AUTOSAR XML (schema 4-3-0)
package /ComponentTypes
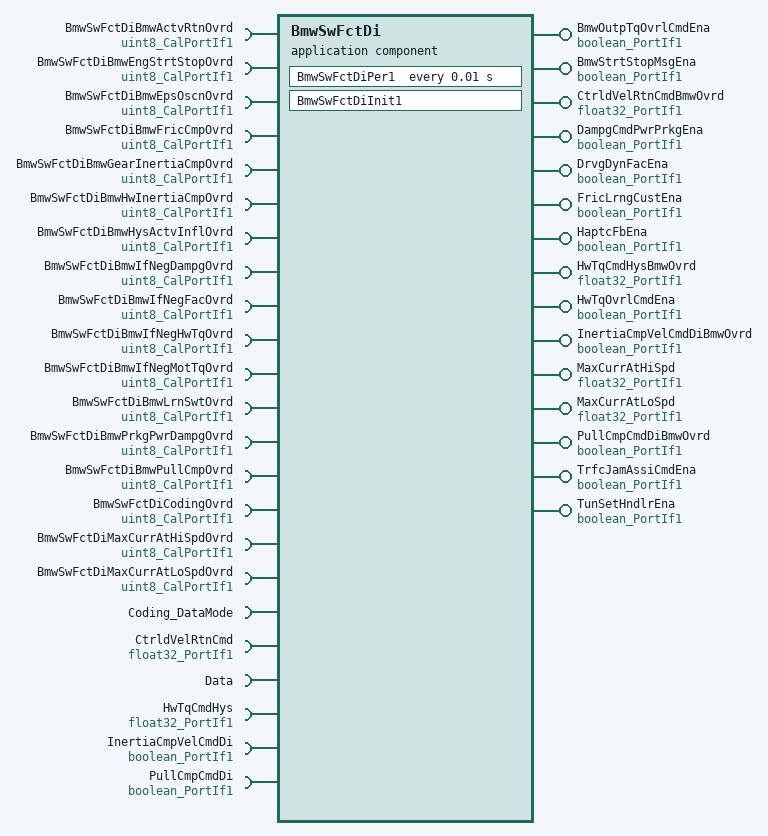
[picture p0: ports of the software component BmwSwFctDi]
  application sw component type BmwSwFctDi
    15 x provide port:
      BmwOutpTqOvrlCmdEna: nonqueued-sender-com-spec{data-element=Logl, init-value=1}, provided-interface=boolean_PortIf1
      BmwStrtStopMsgEna: nonqueued-sender-com-spec{data-element=Logl, init-value=1}, provided-interface=boolean_PortIf1
      CtrldVelRtnCmdBmwOvrd: nonqueued-sender-com-spec{data-element=Val, init-value=0}, provided-interface=float32_PortIf1
      DampgCmdPwrPrkgEna: nonqueued-sender-com-spec{data-element=Logl, init-value=0}, provided-interface=boolean_PortIf1
      DrvgDynFacEna: nonqueued-sender-com-spec{data-element=Logl, init-value=1}, provided-interface=boolean_PortIf1
      FricLrngCustEna: nonqueued-sender-com-spec{data-element=Logl, init-value=1}, provided-interface=boolean_PortIf1
      HaptcFbEna: nonqueued-sender-com-spec{data-element=Logl, init-value=1}, provided-interface=boolean_PortIf1
      HwTqCmdHysBmwOvrd: nonqueued-sender-com-spec{data-element=Val, init-value=0}, provided-interface=float32_PortIf1
      HwTqOvrlCmdEna: nonqueued-sender-com-spec{data-element=Logl, init-value=1}, provided-interface=boolean_PortIf1
      InertiaCmpVelCmdDiBmwOvrd: nonqueued-sender-com-spec{data-element=Logl, init-value=0}, provided-interface=boolean_PortIf1
      MaxCurrAtHiSpd: nonqueued-sender-com-spec{data-element=Val, init-value=0}, provided-interface=float32_PortIf1
      MaxCurrAtLoSpd: nonqueued-sender-com-spec{data-element=Val, init-value=0}, provided-interface=float32_PortIf1
      PullCmpCmdDiBmwOvrd: nonqueued-sender-com-spec{data-element=Logl, init-value=0}, provided-interface=boolean_PortIf1
      TrfcJamAssiCmdEna: nonqueued-sender-com-spec{data-element=Logl, init-value=1}, provided-interface=boolean_PortIf1
      TunSetHndlrEna: nonqueued-sender-com-spec{data-element=Logl, init-value=1}, provided-interface=boolean_PortIf1
    23 x require port:
      BmwSwFctDiBmwActvRtnOvrd: parameter-require-com-spec{init-value=255, parameter=Val}, required-interface=uint8_CalPortIf1
      BmwSwFctDiBmwEngStrtStopOvrd: parameter-require-com-spec{init-value=255, parameter=Val}, required-interface=uint8_CalPortIf1
      BmwSwFctDiBmwEpsOscnOvrd: parameter-require-com-spec{init-value=255, parameter=Val}, required-interface=uint8_CalPortIf1
      BmwSwFctDiBmwFricCmpOvrd: parameter-require-com-spec{init-value=255, parameter=Val}, required-interface=uint8_CalPortIf1
      BmwSwFctDiBmwGearInertiaCmpOvrd: parameter-require-com-spec{init-value=255, parameter=Val}, required-interface=uint8_CalPortIf1
      BmwSwFctDiBmwHwInertiaCmpOvrd: parameter-require-com-spec{init-value=255, parameter=Val}, required-interface=uint8_CalPortIf1
      BmwSwFctDiBmwHysActvInflOvrd: parameter-require-com-spec{init-value=255, parameter=Val}, required-interface=uint8_CalPortIf1
      BmwSwFctDiBmwIfNegDampgOvrd: parameter-require-com-spec{init-value=255, parameter=Val}, required-interface=uint8_CalPortIf1
      BmwSwFctDiBmwIfNegFacOvrd: parameter-require-com-spec{init-value=255, parameter=Val}, required-interface=uint8_CalPortIf1
      BmwSwFctDiBmwIfNegHwTqOvrd: parameter-require-com-spec{init-value=255, parameter=Val}, required-interface=uint8_CalPortIf1
      BmwSwFctDiBmwIfNegMotTqOvrd: parameter-require-com-spec{init-value=255, parameter=Val}, required-interface=uint8_CalPortIf1
      BmwSwFctDiBmwLrnSwtOvrd: parameter-require-com-spec{init-value=255, parameter=Val}, required-interface=uint8_CalPortIf1
      BmwSwFctDiBmwPrkgPwrDampgOvrd: parameter-require-com-spec{init-value=255, parameter=Val}, required-interface=uint8_CalPortIf1
      BmwSwFctDiBmwPullCmpOvrd: parameter-require-com-spec{init-value=255, parameter=Val}, required-interface=uint8_CalPortIf1
      BmwSwFctDiCodingOvrd: parameter-require-com-spec{init-value=0, parameter=Val}, required-interface=uint8_CalPortIf1
      BmwSwFctDiMaxCurrAtHiSpdOvrd: parameter-require-com-spec{init-value=0, parameter=Val}, required-interface=uint8_CalPortIf1
      BmwSwFctDiMaxCurrAtLoSpdOvrd: parameter-require-com-spec{init-value=0, parameter=Val}, required-interface=uint8_CalPortIf1
      Coding_DataMode: mode-switch-receiver-com-spec{enhanced-mode-api=false, supports-asynchronous-mode-switch=false}, required-interface=Coding_DataMode
      CtrldVelRtnCmd: nonqueued-receiver-com-spec{data-element=Val, filter=data-filter-type=ALWAYS, init-value=0}, required-interface=float32_PortIf1
      Data: required-interface=Data
        required-com-specs:
          GetCurrentLimit
          GetNAME00_00_CalculationOfLoadMinusstateMinusdependentSteeringAssistance
          GetNAME00_01_CalculationOfActiveReturn
          GetNAME00_02_reserved
          GetNAME00_03_ActiveInfluenceOnTheSteeringHysterisis
          GetNAME00_{04..07}_reserved
          GetNAME01_{00..02}_reserved
          GetNAME01_03_ParkingPowerDamping
          GetNAME01_{04..07}_reserved
          GetNAME02_00_CompensationOfFriction
          GetNAME02_01_CompensationOfConstantSteeringPullAndLateralInclinationPull
          GetNAME02_02
          GetNAME02_03
          GetNAME02_04_CompensationOfInertiaOfTheSteeringGear
          GetNAME02_05_CompensationOfInertiaOfTheSteeringWheel
          GetNAME02_06
          GetNAME02_07
          GetNAME03_00_reserved
          GetNAME03_01_VoltageDependantDegredation
          GetNAME03_02_SpeedDependantDegredation
          GetNAME03_{03..07}_reserved
          GetNAME04_00_DrivingDynamicsInterfaceMinusDriversTorque
          GetNAME04_00_DrivingDynamicsInterfaceMinusMotorTorque
          GetNAME04_02_DrivingDynamicsInterfaceMinusFactors
          GetNAME04_03_DrivingDynamicsInterfaceMinusAdditionalDamping
          GetNAME04_04_EPSVibration
          GetNAME04_05_DrivingExperienceSwitch
          GetNAME04_06_reserved
          GetNAME04_07_automaticEngineStartStopFunction
          GetNAME05_00_ActiveFanActuation
          GetNAME05_{01..07}_reserved
          GetNAME{08..29}_reserved
          GetSpeedMinuslimitForMaxCurrent
      HwTqCmdHys: nonqueued-receiver-com-spec{data-element=Val, filter=data-filter-type=ALWAYS, init-value=0}, required-interface=float32_PortIf1
      InertiaCmpVelCmdDi: nonqueued-receiver-com-spec{data-element=Logl, filter=data-filter-type=ALWAYS, init-value=0}, required-interface=boolean_PortIf1
      PullCmpCmdDi: nonqueued-receiver-com-spec{data-element=Logl, filter=data-filter-type=ALWAYS, init-value=0}, required-interface=boolean_PortIf1
    behavior BmwSwFctDi_InternalBehavior
      ar-typed-per-instance-memorys:
        15 x data, all with sw-calibration-access=READ-ONLY, type=uint8:
          BmwActvRtn
          BmwEngStrtStop
          BmwEpsOscn
          BmwFricCmp
          BmwGearInertiaCmp
          BmwHwInertiaCmp
          BmwHysActvInfl
          BmwIfNegDampg
          BmwIfNegFac
          BmwIfNegHwTq
          BmwIfNegMotTq
          BmwLrnSwt
          BmwPrkgPwrDampg
          BmwPullCmp
          PrevCodingDataMode
      init event BmwSwFctDi_InitEvent: start-on-event=BmwSwFctDiInit1
      timing event TMT_BmwSwFctDiPer1: start-on-event=BmwSwFctDiPer1, period=0.01
      port-api-options:
        enable-take-address=false, error-handling=NO-TRANSFORMER-ERROR-HANDLING, indirect-api=false, port=BmwOutpTqOvrlCmdEna
        enable-take-address=false, error-handling=NO-TRANSFORMER-ERROR-HANDLING, indirect-api=false, port=BmwStrtStopMsgEna
        enable-take-address=false, error-handling=NO-TRANSFORMER-ERROR-HANDLING, indirect-api=false, port=BmwSwFctDiBmwActvRtnOvrd
        enable-take-address=false, error-handling=NO-TRANSFORMER-ERROR-HANDLING, indirect-api=false, port=BmwSwFctDiBmwEngStrtStopOvrd
        enable-take-address=false, error-handling=NO-TRANSFORMER-ERROR-HANDLING, indirect-api=false, port=BmwSwFctDiBmwEpsOscnOvrd
        enable-take-address=false, error-handling=NO-TRANSFORMER-ERROR-HANDLING, indirect-api=false, port=BmwSwFctDiBmwFricCmpOvrd
        enable-take-address=false, error-handling=NO-TRANSFORMER-ERROR-HANDLING, indirect-api=false, port=BmwSwFctDiBmwGearInertiaCmpOvrd
        enable-take-address=false, error-handling=NO-TRANSFORMER-ERROR-HANDLING, indirect-api=false, port=BmwSwFctDiBmwHwInertiaCmpOvrd
        enable-take-address=false, error-handling=NO-TRANSFORMER-ERROR-HANDLING, indirect-api=false, port=BmwSwFctDiBmwHysActvInflOvrd
        enable-take-address=false, error-handling=NO-TRANSFORMER-ERROR-HANDLING, indirect-api=false, port=BmwSwFctDiBmwIfNegDampgOvrd
        enable-take-address=false, error-handling=NO-TRANSFORMER-ERROR-HANDLING, indirect-api=false, port=BmwSwFctDiBmwIfNegFacOvrd
        enable-take-address=false, error-handling=NO-TRANSFORMER-ERROR-HANDLING, indirect-api=false, port=BmwSwFctDiBmwIfNegHwTqOvrd
        enable-take-address=false, error-handling=NO-TRANSFORMER-ERROR-HANDLING, indirect-api=false, port=BmwSwFctDiBmwIfNegMotTqOvrd
        enable-take-address=false, error-handling=NO-TRANSFORMER-ERROR-HANDLING, indirect-api=false, port=BmwSwFctDiBmwLrnSwtOvrd
        enable-take-address=false, error-handling=NO-TRANSFORMER-ERROR-HANDLING, indirect-api=false, port=BmwSwFctDiBmwPrkgPwrDampgOvrd
        enable-take-address=false, error-handling=NO-TRANSFORMER-ERROR-HANDLING, indirect-api=false, port=BmwSwFctDiBmwPullCmpOvrd
        enable-take-address=false, error-handling=NO-TRANSFORMER-ERROR-HANDLING, indirect-api=false, port=BmwSwFctDiCodingOvrd
        enable-take-address=false, error-handling=NO-TRANSFORMER-ERROR-HANDLING, indirect-api=false, port=BmwSwFctDiMaxCurrAtHiSpdOvrd
        enable-take-address=false, error-handling=NO-TRANSFORMER-ERROR-HANDLING, indirect-api=false, port=BmwSwFctDiMaxCurrAtLoSpdOvrd
        enable-take-address=false, error-handling=NO-TRANSFORMER-ERROR-HANDLING, indirect-api=false, port=Coding_DataMode
        enable-take-address=false, error-handling=NO-TRANSFORMER-ERROR-HANDLING, indirect-api=false, port=CtrldVelRtnCmd
        enable-take-address=false, error-handling=NO-TRANSFORMER-ERROR-HANDLING, indirect-api=false, port=CtrldVelRtnCmdBmwOvrd
        enable-take-address=false, error-handling=NO-TRANSFORMER-ERROR-HANDLING, indirect-api=false, port=DampgCmdPwrPrkgEna
        enable-take-address=false, error-handling=NO-TRANSFORMER-ERROR-HANDLING, indirect-api=false, port=DrvgDynFacEna
        enable-take-address=false, error-handling=NO-TRANSFORMER-ERROR-HANDLING, indirect-api=false, port=FricLrngCustEna
        enable-take-address=false, error-handling=NO-TRANSFORMER-ERROR-HANDLING, indirect-api=false, port=HaptcFbEna
        enable-take-address=false, error-handling=NO-TRANSFORMER-ERROR-HANDLING, indirect-api=false, port=HwTqCmdHys
        enable-take-address=false, error-handling=NO-TRANSFORMER-ERROR-HANDLING, indirect-api=false, port=HwTqCmdHysBmwOvrd
        enable-take-address=false, error-handling=NO-TRANSFORMER-ERROR-HANDLING, indirect-api=false, port=HwTqOvrlCmdEna
        enable-take-address=false, error-handling=NO-TRANSFORMER-ERROR-HANDLING, indirect-api=false, port=InertiaCmpVelCmdDi
        enable-take-address=false, error-handling=NO-TRANSFORMER-ERROR-HANDLING, indirect-api=false, port=InertiaCmpVelCmdDiBmwOvrd
        enable-take-address=false, error-handling=NO-TRANSFORMER-ERROR-HANDLING, indirect-api=false, port=MaxCurrAtHiSpd
        enable-take-address=false, error-handling=NO-TRANSFORMER-ERROR-HANDLING, indirect-api=false, port=MaxCurrAtLoSpd
        enable-take-address=false, error-handling=NO-TRANSFORMER-ERROR-HANDLING, indirect-api=false, port=PullCmpCmdDi
        enable-take-address=false, error-handling=NO-TRANSFORMER-ERROR-HANDLING, indirect-api=false, port=PullCmpCmdDiBmwOvrd
        enable-take-address=false, error-handling=NO-TRANSFORMER-ERROR-HANDLING, indirect-api=false, port=TrfcJamAssiCmdEna
        enable-take-address=false, error-handling=NO-TRANSFORMER-ERROR-HANDLING, indirect-api=false, port=TunSetHndlrEna
      runnable BmwSwFctDiInit1: mode-access-point=Coding_DataMode.Mode
        data-receive-point-by-arguments:
          4 x access:
            REC_CtrldVelRtnCmd_Val: accessed-variable=CtrldVelRtnCmd.Val
            REC_HwTqCmdHys_Val: accessed-variable=HwTqCmdHys.Val
            REC_InertiaCmpVelCmdDi_Logl: accessed-variable=InertiaCmpVelCmdDi.Logl
            REC_PullCmpCmdDi_Logl: accessed-variable=PullCmpCmdDi.Logl
        data-send-points:
          15 x access:
            SEND_BmwOutpTqOvrlCmdEna_Logl: accessed-variable=BmwOutpTqOvrlCmdEna.Logl
            SEND_BmwStrtStopMsgEna_Logl: accessed-variable=BmwStrtStopMsgEna.Logl
            SEND_CtrldVelRtnCmdBmwOvrd_Val: accessed-variable=CtrldVelRtnCmdBmwOvrd.Val
            SEND_DampgCmdPwrPrkgEna_Logl: accessed-variable=DampgCmdPwrPrkgEna.Logl
            SEND_DrvgDynFacEna_Logl: accessed-variable=DrvgDynFacEna.Logl
            SEND_FricLrngCustEna_Logl: accessed-variable=FricLrngCustEna.Logl
            SEND_HaptcFbEna_Logl: accessed-variable=HaptcFbEna.Logl
            SEND_HwTqCmdHysBmwOvrd_Val: accessed-variable=HwTqCmdHysBmwOvrd.Val
            SEND_HwTqOvrlCmdEna_Logl: accessed-variable=HwTqOvrlCmdEna.Logl
            SEND_InertiaCmpVelCmdDiBmwOvrd_Logl: accessed-variable=InertiaCmpVelCmdDiBmwOvrd.Logl
            SEND_MaxCurrAtHiSpd_Val: accessed-variable=MaxCurrAtHiSpd.Val
            SEND_MaxCurrAtLoSpd_Val: accessed-variable=MaxCurrAtLoSpd.Val
            SEND_PullCmpCmdDiBmwOvrd_Logl: accessed-variable=PullCmpCmdDiBmwOvrd.Logl
            SEND_TrfcJamAssiCmdEna_Logl: accessed-variable=TrfcJamAssiCmdEna.Logl
            SEND_TunSetHndlrEna_Logl: accessed-variable=TunSetHndlrEna.Logl
        26 x sync call, all with timeout=0:
          SC_Data_GetCurrentLimit: operation=Data.GetCurrentLimit
          SC_Data_GetNAME00_00_CalculationOfLoadMinusstateMinusdependentSteeringAssistance: operation=Data.GetNAME00_00_CalculationOfLoadMinusstateMinusdependentSteeringAssistance
          SC_Data_GetNAME00_01_CalculationOfActiveReturn: operation=Data.GetNAME00_01_CalculationOfActiveReturn
          SC_Data_GetNAME00_02_reserved: operation=Data.GetNAME00_02_reserved
          SC_Data_GetNAME00_03_ActiveInfluenceOnTheSteeringHysterisis: operation=Data.GetNAME00_03_ActiveInfluenceOnTheSteeringHysterisis
          SC_Data_GetNAME01_03_ParkingPowerDamping: operation=Data.GetNAME01_03_ParkingPowerDamping
          SC_Data_GetNAME02_00_CompensationOfFriction: operation=Data.GetNAME02_00_CompensationOfFriction
          SC_Data_GetNAME02_01_CompensationOfConstantSteeringPullAndLateralInclinationPull: operation=Data.GetNAME02_01_CompensationOfConstantSteeringPullAndLateralInclinationPull
          SC_Data_GetNAME02_02: operation=Data.GetNAME02_02
          SC_Data_GetNAME02_03: operation=Data.GetNAME02_03
          SC_Data_GetNAME02_04_CompensationOfInertiaOfTheSteeringGear: operation=Data.GetNAME02_04_CompensationOfInertiaOfTheSteeringGear
          SC_Data_GetNAME02_05_CompensationOfInertiaOfTheSteeringWheel: operation=Data.GetNAME02_05_CompensationOfInertiaOfTheSteeringWheel
          SC_Data_GetNAME02_06: operation=Data.GetNAME02_06
          SC_Data_GetNAME02_07: operation=Data.GetNAME02_07
          SC_Data_GetNAME03_01_VoltageDependantDegredation: operation=Data.GetNAME03_01_VoltageDependantDegredation
          SC_Data_GetNAME03_02_SpeedDependantDegredation: operation=Data.GetNAME03_02_SpeedDependantDegredation
          SC_Data_GetNAME04_00_DrivingDynamicsInterfaceMinusDriversTorque: operation=Data.GetNAME04_00_DrivingDynamicsInterfaceMinusDriversTorque
          SC_Data_GetNAME04_00_DrivingDynamicsInterfaceMinusMotorTorque: operation=Data.GetNAME04_00_DrivingDynamicsInterfaceMinusMotorTorque
          SC_Data_GetNAME04_02_DrivingDynamicsInterfaceMinusFactors: operation=Data.GetNAME04_02_DrivingDynamicsInterfaceMinusFactors
          SC_Data_GetNAME04_03_DrivingDynamicsInterfaceMinusAdditionalDamping: operation=Data.GetNAME04_03_DrivingDynamicsInterfaceMinusAdditionalDamping
          SC_Data_GetNAME04_04_EPSVibration: operation=Data.GetNAME04_04_EPSVibration
          SC_Data_GetNAME04_05_DrivingExperienceSwitch: operation=Data.GetNAME04_05_DrivingExperienceSwitch
          SC_Data_GetNAME04_06_reserved: operation=Data.GetNAME04_06_reserved
          SC_Data_GetNAME04_07_automaticEngineStartStopFunction: operation=Data.GetNAME04_07_automaticEngineStartStopFunction
          SC_Data_GetNAME05_00_ActiveFanActuation: operation=Data.GetNAME05_00_ActiveFanActuation
          SC_Data_GetSpeedMinuslimitForMaxCurrent: operation=Data.GetSpeedMinuslimitForMaxCurrent
      runnable BmwSwFctDiPer1: mode-access-point=Coding_DataMode.Mode
        data-receive-point-by-arguments:
          4 x access:
            REC_CtrldVelRtnCmd_Val: accessed-variable=CtrldVelRtnCmd.Val
            REC_HwTqCmdHys_Val: accessed-variable=HwTqCmdHys.Val
            REC_InertiaCmpVelCmdDi_Logl: accessed-variable=InertiaCmpVelCmdDi.Logl
            REC_PullCmpCmdDi_Logl: accessed-variable=PullCmpCmdDi.Logl
        data-send-points:
          15 x access:
            SEND_BmwOutpTqOvrlCmdEna_Logl: accessed-variable=BmwOutpTqOvrlCmdEna.Logl
            SEND_BmwStrtStopMsgEna_Logl: accessed-variable=BmwStrtStopMsgEna.Logl
            SEND_CtrldVelRtnCmdBmwOvrd_Val: accessed-variable=CtrldVelRtnCmdBmwOvrd.Val
            SEND_DampgCmdPwrPrkgEna_Logl: accessed-variable=DampgCmdPwrPrkgEna.Logl
            SEND_DrvgDynFacEna_Logl: accessed-variable=DrvgDynFacEna.Logl
            SEND_FricLrngCustEna_Logl: accessed-variable=FricLrngCustEna.Logl
            SEND_HaptcFbEna_Logl: accessed-variable=HaptcFbEna.Logl
            SEND_HwTqCmdHysBmwOvrd_Val: accessed-variable=HwTqCmdHysBmwOvrd.Val
            SEND_HwTqOvrlCmdEna_Logl: accessed-variable=HwTqOvrlCmdEna.Logl
            SEND_InertiaCmpVelCmdDiBmwOvrd_Logl: accessed-variable=InertiaCmpVelCmdDiBmwOvrd.Logl
            SEND_MaxCurrAtHiSpd_Val: accessed-variable=MaxCurrAtHiSpd.Val
            SEND_MaxCurrAtLoSpd_Val: accessed-variable=MaxCurrAtLoSpd.Val
            SEND_PullCmpCmdDiBmwOvrd_Logl: accessed-variable=PullCmpCmdDiBmwOvrd.Logl
            SEND_TrfcJamAssiCmdEna_Logl: accessed-variable=TrfcJamAssiCmdEna.Logl
            SEND_TunSetHndlrEna_Logl: accessed-variable=TunSetHndlrEna.Logl
        27 x sync call, all with timeout=0:
          SC_Data_GetCurrentLimit: operation=Data.GetCurrentLimit
          SC_Data_GetNAME00_00_CalculationOfLoadMinusstateMinusdependentSteeringAssistance: operation=Data.GetNAME00_00_CalculationOfLoadMinusstateMinusdependentSteeringAssistance
          SC_Data_GetNAME00_01_CalculationOfActiveReturn: operation=Data.GetNAME00_01_CalculationOfActiveReturn
          SC_Data_GetNAME00_02_reserved: operation=Data.GetNAME00_02_reserved
          SC_Data_GetNAME00_03_ActiveInfluenceOnTheSteeringHysterisis: operation=Data.GetNAME00_03_ActiveInfluenceOnTheSteeringHysterisis
          SC_Data_GetNAME01_03_ParkingPowerDamping: operation=Data.GetNAME01_03_ParkingPowerDamping
          SC_Data_GetNAME02_00_CompensationOfFriction: operation=Data.GetNAME02_00_CompensationOfFriction
          SC_Data_GetNAME02_01_CompensationOfConstantSteeringPullAndLateralInclinationPull: operation=Data.GetNAME02_01_CompensationOfConstantSteeringPullAndLateralInclinationPull
          SC_Data_GetNAME02_02: operation=Data.GetNAME02_02
          SC_Data_GetNAME02_03: operation=Data.GetNAME02_03
          SC_Data_GetNAME02_04_CompensationOfInertiaOfTheSteeringGear: operation=Data.GetNAME02_04_CompensationOfInertiaOfTheSteeringGear
          SC_Data_GetNAME02_05_CompensationOfInertiaOfTheSteeringWheel: operation=Data.GetNAME02_05_CompensationOfInertiaOfTheSteeringWheel
          SC_Data_GetNAME02_06: operation=Data.GetNAME02_06
          SC_Data_GetNAME02_07: operation=Data.GetNAME02_07
          SC_Data_GetNAME03_00_reserved: operation=Data.GetNAME03_00_reserved
          SC_Data_GetNAME03_01_VoltageDependantDegredation: operation=Data.GetNAME03_01_VoltageDependantDegredation
          SC_Data_GetNAME03_02_SpeedDependantDegredation: operation=Data.GetNAME03_02_SpeedDependantDegredation
          SC_Data_GetNAME04_00_DrivingDynamicsInterfaceMinusDriversTorque: operation=Data.GetNAME04_00_DrivingDynamicsInterfaceMinusDriversTorque
          SC_Data_GetNAME04_00_DrivingDynamicsInterfaceMinusMotorTorque: operation=Data.GetNAME04_00_DrivingDynamicsInterfaceMinusMotorTorque
          SC_Data_GetNAME04_02_DrivingDynamicsInterfaceMinusFactors: operation=Data.GetNAME04_02_DrivingDynamicsInterfaceMinusFactors
          SC_Data_GetNAME04_03_DrivingDynamicsInterfaceMinusAdditionalDamping: operation=Data.GetNAME04_03_DrivingDynamicsInterfaceMinusAdditionalDamping
          SC_Data_GetNAME04_04_EPSVibration: operation=Data.GetNAME04_04_EPSVibration
          SC_Data_GetNAME04_05_DrivingExperienceSwitch: operation=Data.GetNAME04_05_DrivingExperienceSwitch
          SC_Data_GetNAME04_06_reserved: operation=Data.GetNAME04_06_reserved
          SC_Data_GetNAME04_07_automaticEngineStartStopFunction: operation=Data.GetNAME04_07_automaticEngineStartStopFunction
          SC_Data_GetNAME05_00_ActiveFanActuation: operation=Data.GetNAME05_00_ActiveFanActuation
          SC_Data_GetSpeedMinuslimitForMaxCurrent: operation=Data.GetSpeedMinuslimitForMaxCurrent
  swc implementation BmwSwFctDi_Implementation: behavior=BmwSwFctDi_InternalBehavior
    code-descriptors:
      code Default: artifact-descriptors=autosar-engineering-object={short-label=Default, category=SWSRC}
